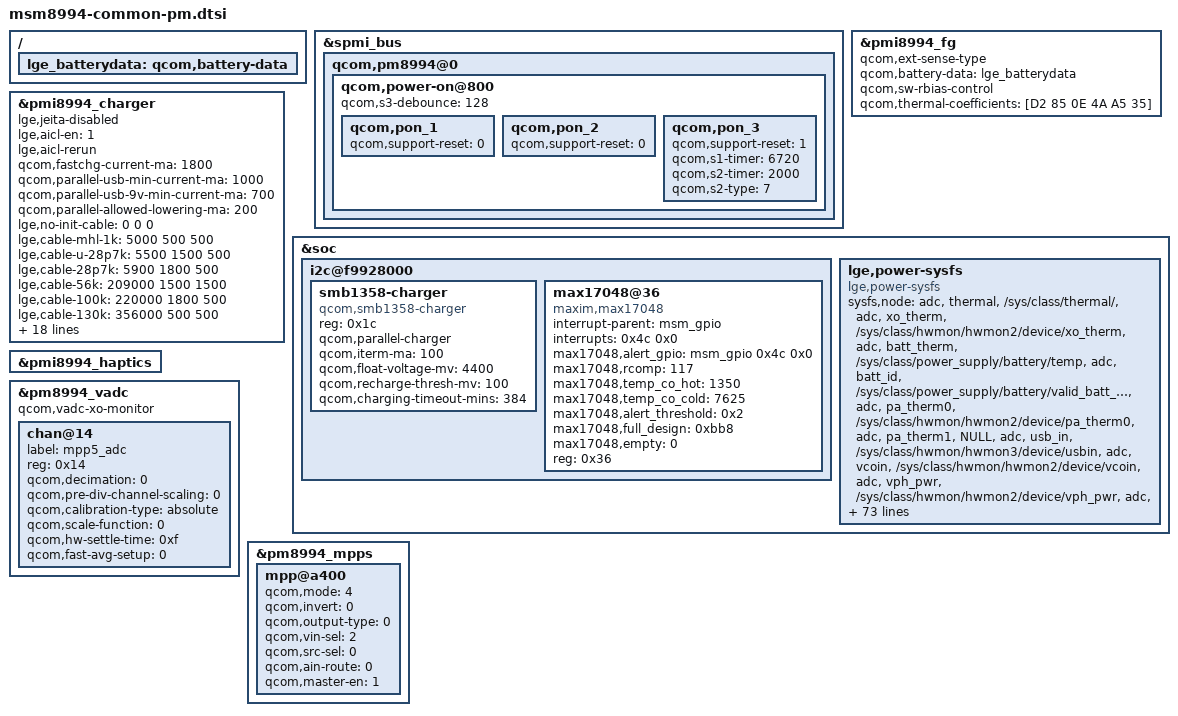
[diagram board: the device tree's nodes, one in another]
&spmi_bus {
	qcom,pm8994@0 {
		qcom,power-on@800 {
			qcom,s3-debounce = <128>;
			qcom,pon_1 { /* KPD_PWR_N reset */
				status = "ok";
				qcom,support-reset = <0>;
			};

			qcom,pon_2 { /* RESIN_N reset   */
				status = "ok";
				qcom,support-reset = <0>;
			};

			qcom,pon_3 { /* KPD_PWR_N AND RESIN_N reset */
				status = "ok";
				qcom,support-reset = <1>;
				qcom,s1-timer = <6720>;
				qcom,s2-timer = <2000>;
				qcom,s2-type = <7>;
			};
		};
	};
};

/{
	lge_batterydata: qcom,battery-data {
		#include "batterydata-lge-blt16-4v35-3000mah.dtsi"
	};
};

&pmi8994_fg {
	status = "ok";

	qcom,ext-sense-type;
	qcom,battery-data = <&lge_batterydata>;
	qcom,sw-rbias-control;
	qcom,thermal-coefficients = [D2 85 0E 4A A5 35];
};

&pmi8994_charger {
	status = "ok";

	lge,jeita-disabled;
	lge,aicl-en = <1>;
	lge,aicl-rerun;
	qcom,fastchg-current-ma = <1800>;
	qcom,parallel-usb-min-current-ma = <1000>;
	qcom,parallel-usb-9v-min-current-ma = <700>;
	qcom,parallel-allowed-lowering-ma = <200>;

	lge,no-init-cable = <0 0 0>;
	lge,cable-mhl-1k = <5000 500 500>;
	lge,cable-u-28p7k = <5500 1500 500>;
	lge,cable-28p7k = <5900 1800 500>;
	lge,cable-56k = <209000 1500 1500>;
	lge,cable-100k = <220000 1800 500>;
	lge,cable-130k = <356000 500 500>;
	lge,cable-180k = <422000 1800 500>;
	lge,cable-200k = <433000 1800 500>;
	lge,cable-220k = <509000 1800 500>;
	lge,cable-270k = <586000 1800 500>;
	lge,cable-330k = <763000 1800 500>;
	lge,cable-620k = <971000 1800 500>;
	lge,cable-910k = <1172000 1500 1500>;
	lge,cable-none = <1900000 1800  500>;
	qcom,iterm-ma = <100>;
	qcom,float-voltage-mv = <4350>;
	qcom,resume-delta-mv = <200>;
	qcom,charge-unknown-battery;
	qcom,charging-timeout-mins = <768>;
	qcom,chg-vadc = <&pmi8994_vadc>;
	qcom,smb-vadc = <&pm8994_vadc>;
	qcom,dc-psy-type;
	qcom,bmd-pin-src="bpd_none";
	vddcx-supply = <&pm8994_s1_corner>; /* VDD_CX_VOTE */
};

&soc {
	i2c@f9928000 { /* BLSP1 QUP6 */
		status = "ok";
		smb1358-charger{
			status = "ok";
			compatible = "qcom,smb1358-charger";
			reg = <0x1c>;
			qcom,parallel-charger;
			qcom,iterm-ma = <100>;
			qcom,float-voltage-mv = <4400>;
			qcom,recharge-thresh-mv = <100>;
			qcom,charging-timeout-mins = <384>;
		};

		max17048@36 {
			status = "ok";
			compatible = "maxim,max17048";
			interrupt-parent = <&msm_gpio>;
			interrupts = <0x4c 0x0>;
			max17048,alert_gpio = <&msm_gpio 0x4c 0x0>;
			max17048,rcomp = <117>;
			max17048,temp_co_hot = <1350>;
			max17048,temp_co_cold = <7625>;
			max17048,alert_threshold = <0x2>;
			max17048,full_design = <0xbb8>;
			max17048,empty = <0>;
			reg = <0x36>;
		};
	};

	lge,power-sysfs {
		compatible = "lge,power-sysfs";

		sysfs,node =
			/* group , user_node,  kernel node */
			/* ADC/MPP */
			"adc", "thermal", "/sys/class/thermal/",
			"adc", "xo_therm", "/sys/class/hwmon/hwmon2/device/xo_therm",
			"adc", "batt_therm", "/sys/class/power_supply/battery/temp",
			"adc", "batt_id", "/sys/class/power_supply/battery/valid_batt_id",
			"adc", "pa_therm0", "/sys/class/hwmon/hwmon2/device/pa_therm0",
			"adc", "pa_therm1", "NULL",
			"adc", "usb_in", "/sys/class/hwmon/hwmon3/device/usbin",
			"adc", "vcoin", "/sys/class/hwmon/hwmon2/device/vcoin",
			"adc", "vph_pwr", "/sys/class/hwmon/hwmon2/device/vph_pwr",
			"adc", "usb_id", "/sys/class/hwmon/hwmon2/device/usb_id_lv",
			/* Battery */
			"battery", "capacity", "/sys/class/power_supply/battery/capacity",
			"battery", "health", "/sys/class/power_supply/battery/health",
			"battery", "present", "/sys/class/power_supply/battery/present",
			"battery", "pseudo_batt", "/sys/class/power_supply/battery/pseudo_batt",
			"battery", "status", "/sys/class/power_supply/battery/status",
			"battery", "temp", "/sys/class/power_supply/battery/temp",
			"battery", "valid_batt_id", "/sys/class/power_supply/battery/valid_batt_id",
			"battery", "voltage_now", "/sys/class/power_supply/battery/voltage_now",
			/* Charger */
			"charger", "ac_online", "NULL",
			"charger", "usb_online", "/sys/class/power_supply/usb/online",
			"charger", "present", "/sys/class/power_supply/usb/present",
			"charger", "wlc_online", "NULL",
			"charger", "type", "/sys/class/power_supply/usb/type",
			"charger", "time_out", "/sys/class/power_supply/battery/safety_timer_enabled",
			"charger", "charging_enabled", "/sys/class/power_supply/battery/charging_enabled",
			"charger", "ibat_current", "/sys/class/power_supply/battery/current_now",
			"charger", "ichg_current", "/sys/class/power_supply/usb/current_max",
			"charger", "iusb_control", "NULL",
			"charger", "thermal_mitigation", "/sys/class/power_supply/battery/system_temp_level",
			"charger", "wlc_thermal_mitigation", "NULL",
			"charger", "usb_parallel_chg_status", "/sys/class/power_supply/usb-parallel/status",
			"charger", "usb_parallel_charging_enabled", "/sys/class/power_supply/usb-parallel/charging_enabled",
			/* LCD Backlight */
			"lcd", "brightness", "/sys/class/leds/lcd-backlight/brightness",
			"lcd", "max_brightness", "/sys/class/leds/lcd-backlight/max_brightness",
			/* KEY LED */
			"key_led", "red_brightness", "/sys/class/leds/red/brightness",
			"key_led", "green_brightness", "/sys/class/leds/green/brightness",
			"key_led", "blue_brightness", "/sys/class/leds/blue/brightness",
			/* CPU */
			"cpu", "cpu_idle_modes", "/sys/module/lpm_levels/system/",
			/* GPU */
			"gpu", "busy", "/sys/class/kgsl/kgsl-3d0/gpubusy",
			/* PLATFORM */
			"platform", "speed_bin", "NULL",
			"platform", "pvs_bin", "NULL",
			"platform", "power_state", "/sys/power/autosleep",
			"platform", "poweron_alarm", "/sys/module/qpnp_rtc/parameters/poweron_alarm",
			"platform", "pcb_rev", "/sys/class/hwmon/hwmon2/device/pcb_rev",
			/* testmode */
			"testmode", "charge", "/sys/class/power_supply/battery/charging_enabled",
			"testmode", "chcomp", "/sys/class/power_supply/battery/device/at_chcomp",
			"testmode", "chgmodeoff", "/sys/class/power_supply/battery/charging_enabled",
			"testmode", "fuelrst", "/sys/bus/i2c/devices/6-0036/fuelrst",
			"testmode", "rtc_time", "/dev/rtc0",
			"testmode", "pmrst", "/sys/class/power_supply/battery/device/at_pmrst",
			"testmode", "battexit", "/sys/class/power_supply/battery/present"
			;
	};
};

&pmi8994_haptics {
	status = "okay";
};

&pm8994_vadc {
	qcom,vadc-xo-monitor;

	chan@14{
		status = "ok";
		label ="mpp5_adc";
		reg = <0x14>;
		qcom,decimation = <0>;
		qcom,pre-div-channel-scaling = <0>;
		qcom,calibration-type = "absolute";
		qcom,scale-function = <0>;
		qcom,hw-settle-time = <0xf>;
		qcom,fast-avg-setup = <0>;
	};
};

&pm8994_mpps {
	mpp@a400 { /* MPP 5 */
		status = "ok";
		qcom,mode = <4>;
		qcom,invert = <0>;
		qcom,output-type = <0>;         /* CMOS logic */
		qcom,vin-sel = <2>;             /* S4 1.8V */
		qcom,src-sel = <0>;             /* Constant */
		qcom,ain-route = <0>;           /* Channel */
		qcom,master-en = <1>;           /* Enable GPIO */
	};

};
